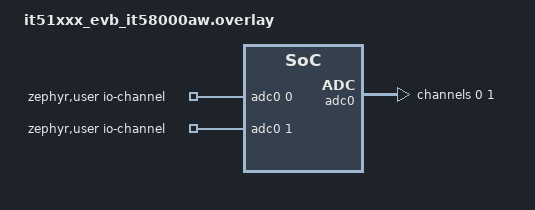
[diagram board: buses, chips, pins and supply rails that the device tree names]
/*
 * Copyright (c) 2026 ITE Corporation. All Rights Reserved.
 *
 * SPDX-License-Identifier: Apache-2.0
 */

/ {
	zephyr,user {
		io-channels = <&adc0 0>, <&adc0 1>;
	};
};

&adc0 {
	#address-cells = <1>;
	#size-cells = <0>;

	pinctrl-0 = <&adc0_ch0_gpi0_default &adc0_ch1_gpi1_default>;
	pinctrl-names = "default";

	channel@0 {
		reg = <0>;
		zephyr,gain = "ADC_GAIN_1";
		zephyr,reference = "ADC_REF_INTERNAL";
		zephyr,vref-mv = <3300>;
		zephyr,acquisition-time = <ADC_ACQ_TIME_DEFAULT>;
		zephyr,resolution = <12>;
	};

	channel@1 {
		reg = <1>;
		zephyr,gain = "ADC_GAIN_1";
		zephyr,reference = "ADC_REF_INTERNAL";
		zephyr,vref-mv = <3300>;
		zephyr,acquisition-time = <ADC_ACQ_TIME_DEFAULT>;
		zephyr,resolution = <12>;
	};
};
